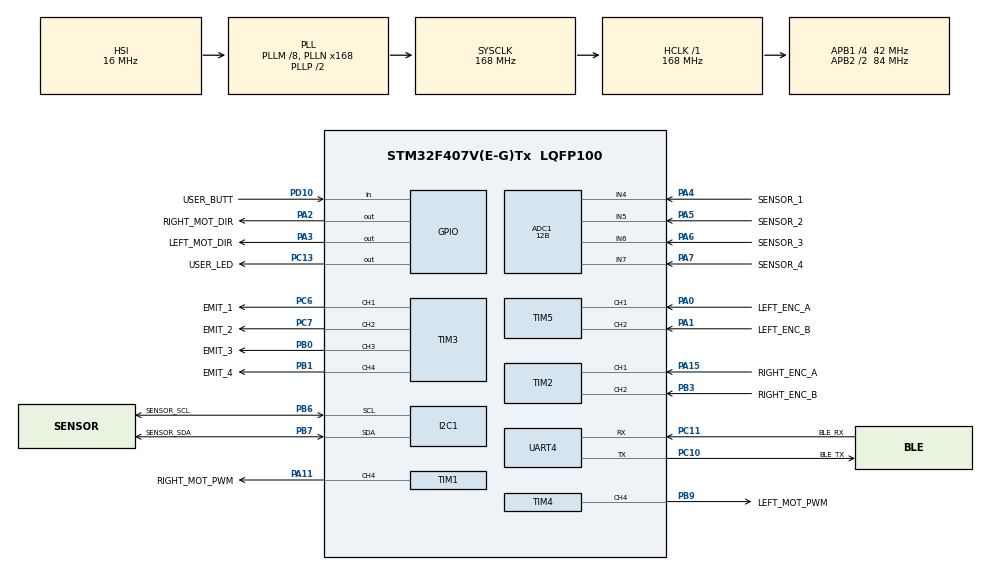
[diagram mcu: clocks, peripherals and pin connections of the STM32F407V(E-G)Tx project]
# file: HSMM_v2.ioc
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ADC1.Channel-1\#ChannelRegularConversion=ADC_CHANNEL_4
ADC1.Channel-5\#ChannelRegularConversion=ADC_CHANNEL_5
ADC1.Channel-6\#ChannelRegularConversion=ADC_CHANNEL_6
ADC1.Channel-7\#ChannelRegularConversion=ADC_CHANNEL_7
ADC1.ClockPrescaler=ADC_CLOCK_SYNC_PCLK_DIV4
ADC1.EOCSelection=ADC_EOC_SINGLE_CONV
ADC1.NbrOfConversion=4
ADC1.NbrOfConversionFlag=1
ADC1.Rank-1\#ChannelRegularConversion=1
ADC1.Rank-5\#ChannelRegularConversion=2
ADC1.Rank-6\#ChannelRegularConversion=3
ADC1.Rank-7\#ChannelRegularConversion=4
ADC1.Resolution=ADC_RESOLUTION_12B
ADC1.SamplingTime-1\#ChannelRegularConversion=ADC_SAMPLETIME_56CYCLES
ADC1.SamplingTime-5\#ChannelRegularConversion=ADC_SAMPLETIME_56CYCLES
ADC1.SamplingTime-6\#ChannelRegularConversion=ADC_SAMPLETIME_56CYCLES
ADC1.SamplingTime-7\#ChannelRegularConversion=ADC_SAMPLETIME_56CYCLES
ADC1.ScanConvMode=ENABLE
ADC1.master=1
I2C1.I2C_Mode=I2C_Fast
Mcu.Family=STM32F4
Mcu.Name=STM32F407V(E-G)Tx
Mcu.Package=LQFP100
NVIC.PriorityGroup=NVIC_PRIORITYGROUP_4
PA0-WKUP.GPIO_Label=LEFT_ENC_A
PA0-WKUP.Signal=S_TIM5_CH1
PA1.GPIO_Label=LEFT_ENC_B
PA1.Signal=S_TIM5_CH2
PA11.GPIO_Label=RIGHT_MOT_PWM
PA11.Signal=S_TIM1_CH4
PA13.Signal=SYS_JTMS-SWDIO
PA14.Signal=SYS_JTCK-SWCLK
PA15.GPIO_Label=RIGHT_ENC_A
PA15.Signal=S_TIM2_CH1_ETR
PA2.GPIO_Label=RIGHT_MOT_DIR
PA2.Signal=GPIO_Output
PA3.GPIO_Label=LEFT_MOT_DIR
PA3.Signal=GPIO_Output
PA4.GPIO_Label=SENSOR_1
PA4.Signal=ADCx_IN4
PA5.GPIO_Label=SENSOR_2
PA5.Signal=ADCx_IN5
PA6.GPIO_Label=SENSOR_3
PA6.Signal=ADCx_IN6
PA7.GPIO_Label=SENSOR_4
PA7.Signal=ADCx_IN7
PB0.GPIO_Label=EMIT_3
PB0.Signal=S_TIM3_CH3
PB1.GPIO_Label=EMIT_4
PB1.Signal=S_TIM3_CH4
PB3.GPIO_Label=RIGHT_ENC_B
PB3.Signal=S_TIM2_CH2
PB6.GPIO_Label=SENSOR_SCL
PB6.Mode=I2C
PB6.Signal=I2C1_SCL
PB7.GPIO_Label=SENSOR_SDA
PB7.Mode=I2C
PB7.Signal=I2C1_SDA
PB9.GPIO_Label=LEFT_MOT_PWM
PB9.Signal=S_TIM4_CH4
PC10.GPIO_Label=BLE_TX
PC10.Mode=Asynchronous
PC10.Signal=UART4_TX
PC11.GPIO_Label=BLE_RX
PC11.Mode=Asynchronous
PC11.Signal=UART4_RX
PC13-ANTI_TAMP.GPIO_Label=USER_LED
PC13-ANTI_TAMP.Signal=GPIO_Output
PC6.GPIO_Label=EMIT_1
PC6.Signal=S_TIM3_CH1
PC7.GPIO_Label=EMIT_2
PC7.Signal=S_TIM3_CH2
PD10.GPIO_Label=USER_BUTT
PD10.Signal=GPIO_Input
ProjectManager.HeapSize=0x200
ProjectManager.StackSize=0x400
ProjectManager.TargetToolchain=MDK-ARM V5
RCC.48MHZClocksFreq_Value=84000000
RCC.AHBFreq_Value=168000000
RCC.APB1CLKDivider=RCC_HCLK_DIV4
RCC.APB1Freq_Value=42000000
RCC.APB1TimFreq_Value=84000000
RCC.APB2CLKDivider=RCC_HCLK_DIV2
RCC.APB2Freq_Value=84000000
RCC.APB2TimFreq_Value=168000000
RCC.CortexFreq_Value=168000000
RCC.HCLKFreq_Value=168000000
RCC.HSE_VALUE=25000000
RCC.HSI_VALUE=16000000
RCC.LSE_VALUE=32768
RCC.PLLM=8
RCC.PLLN=168
RCC.SYSCLKFreq_VALUE=168000000
RCC.SYSCLKSource=RCC_SYSCLKSOURCE_PLLCLK
RCC.VCOOutputFreq_Value=336000000
SH.ADCx_IN4.0=ADC1_IN4,IN4
SH.ADCx_IN5.0=ADC1_IN5,IN5
SH.ADCx_IN6.0=ADC1_IN6,IN6
SH.ADCx_IN7.0=ADC1_IN7,IN7
SH.S_TIM1_CH4.0=TIM1_CH4,PWM Generation4 CH4
SH.S_TIM2_CH1_ETR.0=TIM2_CH1,Encoder_Interface
SH.S_TIM2_CH2.0=TIM2_CH2,Encoder_Interface
SH.S_TIM3_CH1.0=TIM3_CH1,PWM Generation1 CH1
SH.S_TIM3_CH2.0=TIM3_CH2,PWM Generation2 CH2
SH.S_TIM3_CH3.0=TIM3_CH3,PWM Generation3 CH3
SH.S_TIM3_CH4.0=TIM3_CH4,PWM Generation4 CH4
SH.S_TIM4_CH4.0=TIM4_CH4,PWM Generation4 CH4
SH.S_TIM5_CH1.0=TIM5_CH1,Encoder_Interface
SH.S_TIM5_CH2.0=TIM5_CH2,Encoder_Interface
TIM1.Channel-PWM\ Generation4\ CH4=TIM_CHANNEL_4
TIM3.Channel-PWM\ Generation1\ CH1=TIM_CHANNEL_1
TIM3.Channel-PWM\ Generation2\ CH2=TIM_CHANNEL_2
TIM3.Channel-PWM\ Generation3\ CH3=TIM_CHANNEL_3
TIM3.Channel-PWM\ Generation4\ CH4=TIM_CHANNEL_4
TIM4.Channel-PWM\ Generation4\ CH4=TIM_CHANNEL_4
UART4.VirtualMode=Asynchronous
board=custom

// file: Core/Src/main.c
/* USER CODE BEGIN Header */
/**
  ******************************************************************************
  * @file           : main.c
  * @brief          : Main program body
  ******************************************************************************
  * @attention
  *
  * Copyright (c) 2025 STMicroelectronics.
  * All rights reserved.
  *
  * This software is licensed under terms that can be found in the LICENSE file
  * in the root directory of this software component.
  * If no LICENSE file comes with this software, it is provided AS-IS.
  *
  ******************************************************************************
  */
/* USER CODE END Header */
#include "main.h"
#include "adc.h"
#include "i2c.h"
#include "tim.h"
#include "usart.h"
#include "gpio.h"

/* USER CODE BEGIN Includes */
#include "init.h"
/* USER CODE END Includes */

/* USER CODE BEGIN PV */
extern MenuContext sysMenu;
SensorRawData sensorData;
SensorDistData sensorDistData;
int adcConversionComplete=0;
/* USER CODE END PV */

void SystemClock_Config(void);

int main(void)
{

  /* MCU Configuration--------------------------------------------------------*/

  /* Reset of all peripherals, Initializes the Flash interface and the Systick. */
  HAL_Init();

  /* Configure the system clock */
  SystemClock_Config();

  /* Initialize all configured peripherals */
  MX_GPIO_Init();
  MX_ADC1_Init();
  MX_I2C1_Init();
  MX_TIM2_Init();
  MX_TIM3_Init();
  MX_TIM5_Init();
  MX_UART4_Init();
  MX_TIM4_Init();
  MX_TIM1_Init();
  /* USER CODE BEGIN 2 */
	INIT_All();

	SSD1306_Clear();
  /* USER CODE END 2 */

  /* Infinite loop */
  while (1)
  {

    /* USER CODE BEGIN 3 */
		int16_t scrollNow = TIM2->CNT;
    int16_t selectNow = TIM5->CNT;

    Menu_UpdateEncoderInputs(scrollNow, selectNow);
    Menu_Render(&sysMenu);
		HAL_Delay(500);
//		  HAL_GPIO_WritePin(EMIT_1_GPIO_Port,EMIT_1_Pin,0);
//			HAL_Delay(500);
//			HAL_GPIO_WritePin(EMIT_1_GPIO_Port,EMIT_1_Pin,1);
//			HAL_Delay(500);

  }
  /* USER CODE END 3 */
}

void SystemClock_Config(void)
{
  RCC_OscInitTypeDef RCC_OscInitStruct = {0};
  RCC_ClkInitTypeDef RCC_ClkInitStruct = {0};

  /** Configure the main internal regulator output voltage
  */
  __HAL_RCC_PWR_CLK_ENABLE();
  __HAL_PWR_VOLTAGESCALING_CONFIG(PWR_REGULATOR_VOLTAGE_SCALE1);

  /** Initializes the RCC Oscillators according to the specified parameters
  * in the RCC_OscInitTypeDef structure.
  */
  RCC_OscInitStruct.OscillatorType = RCC_OSCILLATORTYPE_HSI;
  RCC_OscInitStruct.HSIState = RCC_HSI_ON;
  RCC_OscInitStruct.HSICalibrationValue = RCC_HSICALIBRATION_DEFAULT;
  RCC_OscInitStruct.PLL.PLLState = RCC_PLL_ON;
  RCC_OscInitStruct.PLL.PLLSource = RCC_PLLSOURCE_HSI;
  RCC_OscInitStruct.PLL.PLLM = 8;
  RCC_OscInitStruct.PLL.PLLN = 168;
  RCC_OscInitStruct.PLL.PLLP = RCC_PLLP_DIV2;
  RCC_OscInitStruct.PLL.PLLQ = 4;
  if (HAL_RCC_OscConfig(&RCC_OscInitStruct) != HAL_OK)
  {
    Error_Handler();
  }

  /** Initializes the CPU, AHB and APB buses clocks
  */
  RCC_ClkInitStruct.ClockType = RCC_CLOCKTYPE_HCLK|RCC_CLOCKTYPE_SYSCLK
                              |RCC_CLOCKTYPE_PCLK1|RCC_CLOCKTYPE_PCLK2;
  RCC_ClkInitStruct.SYSCLKSource = RCC_SYSCLKSOURCE_PLLCLK;
  RCC_ClkInitStruct.AHBCLKDivider = RCC_SYSCLK_DIV1;
  RCC_ClkInitStruct.APB1CLKDivider = RCC_HCLK_DIV4;
  RCC_ClkInitStruct.APB2CLKDivider = RCC_HCLK_DIV2;

  if (HAL_RCC_ClockConfig(&RCC_ClkInitStruct, FLASH_LATENCY_5) != HAL_OK)
  {
    Error_Handler();
  }
}

/* USER CODE BEGIN 4 */
// Call this from main with absolute encoder counts

/* USER CODE END 4 */

void Error_Handler(void)
{
  __disable_irq();
  while (1)
  {
  }
}
